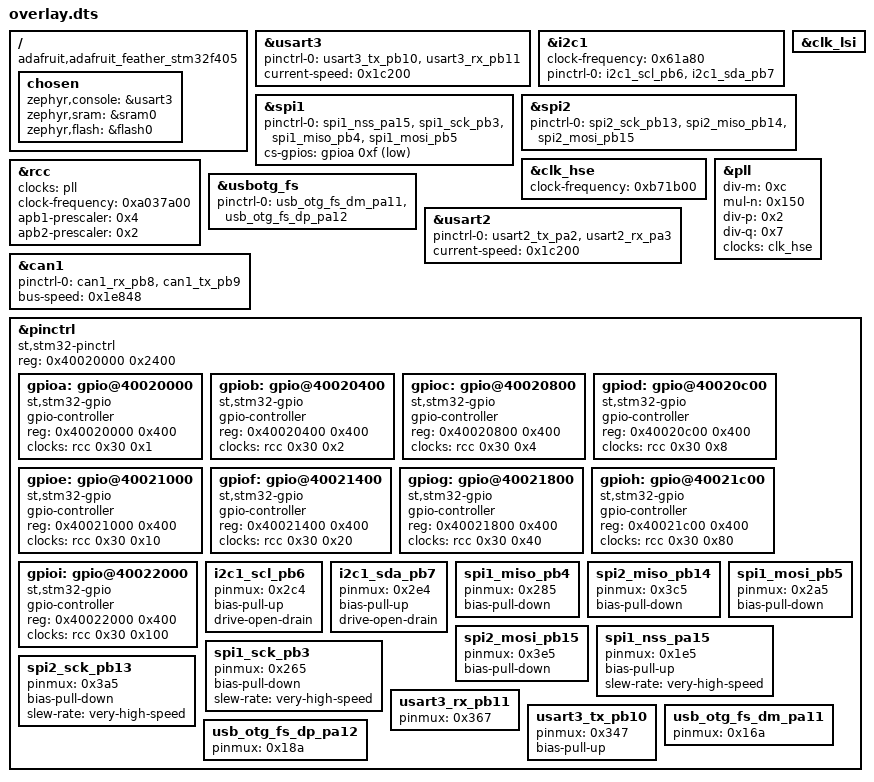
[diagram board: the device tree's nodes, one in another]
/ {
	compatible = "adafruit,adafruit_feather_stm32f405", "st,stm32f405";
	chosen {
		zephyr,console = &usart3;
		zephyr,sram = &sram0;
		zephyr,flash = &flash0;
	};
};
&usart3{
	status = "okay";
	pinctrl-0 = < &usart3_tx_pb10 &usart3_rx_pb11 >;
	pinctrl-names = "default";
	current-speed = < 0x1c200 >;
};
&i2c1{
	clock-frequency = < 0x61a80 >;
	status = "okay";
	pinctrl-0 = < &i2c1_scl_pb6 &i2c1_sda_pb7 >;
	pinctrl-names = "default";
};
&clk_lsi{
	status = "okay";
};
&spi1{
	status = "okay";
	pinctrl-0 = < &spi1_nss_pa15 &spi1_sck_pb3 &spi1_miso_pb4 &spi1_mosi_pb5 >;
	pinctrl-names = "default";
	cs-gpios = < &gpioa 0xf 0x1 >;
};
&spi2{
	status = "okay";
	pinctrl-0 = < &spi2_sck_pb13 &spi2_miso_pb14 &spi2_mosi_pb15 >;
	pinctrl-names = "default";
};
&clk_hse{
	status = "okay";
	clock-frequency = < 0xb71b00 >;
};
&rcc{
	clocks = < &pll >;
	clock-frequency = < 0xa037a00 >;
	apb1-prescaler = < 0x4 >;
	apb2-prescaler = < 0x2 >;
};
&pll{
	status = "okay";
	div-m = < 0xc >;
	mul-n = < 0x150 >;
	div-p = < 0x2 >;
	div-q = < 0x7 >;
	clocks = < &clk_hse >;
};
&usbotg_fs{
	status = "okay";
	pinctrl-0 = < &usb_otg_fs_dm_pa11 &usb_otg_fs_dp_pa12 >;
	pinctrl-names = "default";
};
&usart2{
	status = "okay";
	pinctrl-0 = < &usart2_tx_pa2 &usart2_rx_pa3 >;
	pinctrl-names = "default";
	current-speed = < 0x1c200 >;
};
&can1{
	status = "okay";
	pinctrl-0 = < &can1_rx_pb8 &can1_tx_pb9 >;
	pinctrl-names = "default";
	bus-speed = < 0x1e848 >;
};
&pinctrl{
	compatible = "st,stm32-pinctrl";
	#address-cells = < 0x1 >;
	#size-cells = < 0x1 >;
	reg = < 0x40020000 0x2400 >;
	gpioa: gpio@40020000 {
		compatible = "st,stm32-gpio";
		gpio-controller;
		#gpio-cells = < 0x2 >;
		reg = < 0x40020000 0x400 >;
		clocks = < &rcc 0x30 0x1 >;
	};
	gpiob: gpio@40020400 {
		compatible = "st,stm32-gpio";
		gpio-controller;
		#gpio-cells = < 0x2 >;
		reg = < 0x40020400 0x400 >;
		clocks = < &rcc 0x30 0x2 >;
	};
	gpioc: gpio@40020800 {
		compatible = "st,stm32-gpio";
		gpio-controller;
		#gpio-cells = < 0x2 >;
		reg = < 0x40020800 0x400 >;
		clocks = < &rcc 0x30 0x4 >;
	};
	gpiod: gpio@40020c00 {
		compatible = "st,stm32-gpio";
		gpio-controller;
		#gpio-cells = < 0x2 >;
		reg = < 0x40020c00 0x400 >;
		clocks = < &rcc 0x30 0x8 >;
	};
	gpioe: gpio@40021000 {
		compatible = "st,stm32-gpio";
		gpio-controller;
		#gpio-cells = < 0x2 >;
		reg = < 0x40021000 0x400 >;
		clocks = < &rcc 0x30 0x10 >;
	};
	gpiof: gpio@40021400 {
		compatible = "st,stm32-gpio";
		gpio-controller;
		#gpio-cells = < 0x2 >;
		reg = < 0x40021400 0x400 >;
		clocks = < &rcc 0x30 0x20 >;
	};
	gpiog: gpio@40021800 {
		compatible = "st,stm32-gpio";
		gpio-controller;
		#gpio-cells = < 0x2 >;
		reg = < 0x40021800 0x400 >;
		clocks = < &rcc 0x30 0x40 >;
	};
	gpioh: gpio@40021c00 {
		compatible = "st,stm32-gpio";
		gpio-controller;
		#gpio-cells = < 0x2 >;
		reg = < 0x40021c00 0x400 >;
		clocks = < &rcc 0x30 0x80 >;
	};
	gpioi: gpio@40022000 {
		compatible = "st,stm32-gpio";
		gpio-controller;
		#gpio-cells = < 0x2 >;
		reg = < 0x40022000 0x400 >;
		clocks = < &rcc 0x30 0x100 >;
	};
	i2c1_scl_pb6: i2c1_scl_pb6 {
		pinmux = < 0x2c4 >;
		bias-pull-up;
		drive-open-drain;
	};
	i2c1_sda_pb7: i2c1_sda_pb7 {
		pinmux = < 0x2e4 >;
		bias-pull-up;
		drive-open-drain;
	};
	spi1_miso_pb4: spi1_miso_pb4 {
		pinmux = < 0x285 >;
		bias-pull-down;
	};
	spi2_miso_pb14: spi2_miso_pb14 {
		pinmux = < 0x3c5 >;
		bias-pull-down;
	};
	spi1_mosi_pb5: spi1_mosi_pb5 {
		pinmux = < 0x2a5 >;
		bias-pull-down;
	};
	spi2_mosi_pb15: spi2_mosi_pb15 {
		pinmux = < 0x3e5 >;
		bias-pull-down;
	};
	spi1_nss_pa15: spi1_nss_pa15 {
		pinmux = < 0x1e5 >;
		bias-pull-up;
		slew-rate = "very-high-speed";
	};
	spi1_sck_pb3: spi1_sck_pb3 {
		pinmux = < 0x265 >;
		bias-pull-down;
		slew-rate = "very-high-speed";
	};
	spi2_sck_pb13: spi2_sck_pb13 {
		pinmux = < 0x3a5 >;
		bias-pull-down;
		slew-rate = "very-high-speed";
	};
	usart3_rx_pb11: usart3_rx_pb11 {
		pinmux = < 0x367 >;
	};
	usart3_tx_pb10: usart3_tx_pb10 {
		pinmux = < 0x347 >;
		bias-pull-up;
	};
	usb_otg_fs_dm_pa11: usb_otg_fs_dm_pa11 {
		pinmux = < 0x16a >;
	};
	usb_otg_fs_dp_pa12: usb_otg_fs_dp_pa12 {
		pinmux = < 0x18a >;
	};
};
